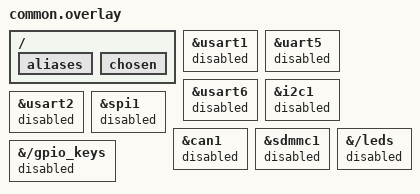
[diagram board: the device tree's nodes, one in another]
/ {
    aliases {
        /delete-property/ sdhc0;
    };

    chosen {
        /delete-property/ zephyr,console;
        /delete-property/ zephyr,shell-uart;
        /delete-property/ zephyr,sdhc;
    };
};

&usart1 {
    status = "disabled";
};

&uart5 {
    status = "disabled";
};

&usart6 {
    status = "disabled";
};

&i2c1 {
    status = "disabled";
};

&usart2 {
    status = "disabled";
};

&spi1 {
    status = "disabled";
};

&can1 {
    status = "disabled";
};

&sdmmc1 {
    status = "disabled";
};

&{/leds} {
    status = "disabled";
};

&{/gpio_keys} {
    status = "disabled";
};
